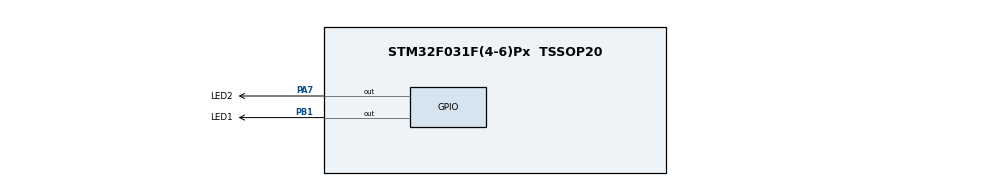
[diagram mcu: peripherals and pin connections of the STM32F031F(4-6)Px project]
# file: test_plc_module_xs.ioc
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Mcu.Family=STM32F0
Mcu.Name=STM32F031F(4-6)Px
Mcu.Package=TSSOP20
NVIC.FLASH_IRQn=true\:0\:0\:false\:false\:true\:true\:true
PA13.Mode=Serial_Wire
PA13.Signal=SYS_SWDIO
PA14.Mode=Serial_Wire
PA14.Signal=SYS_SWCLK
PA7.GPIO_Label=LED2
PA7.Signal=GPIO_Output
PB1.GPIO_Label=LED1
PB1.PinState=GPIO_PIN_SET
PB1.Signal=GPIO_Output
ProjectManager.HeapSize=0x600
ProjectManager.StackSize=0x600
ProjectManager.TargetToolchain=MDK-ARM V5
RCC.AHBFreq_Value=8000000
RCC.APB1Freq_Value=8000000
RCC.APB1TimFreq_Value=8000000
RCC.HCLKFreq_Value=8000000
RCC.HSE_VALUE=16000000
RCC.PLLMUL=RCC_PLL_MUL3
RCC.SYSCLKFreq_VALUE=8000000
board=custom

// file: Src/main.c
/* USER CODE BEGIN Header */
/**
  ******************************************************************************
  * @file           : main.c
  * @brief          : Main program body
  ******************************************************************************
  * @attention
  *
  * <h2><center>&copy; Copyright (c) 2019 STMicroelectronics.
  * All rights reserved.</center></h2>
  *
  * This software component is licensed by ST under BSD 3-Clause license,
  * the "License"; You may not use this file except in compliance with the
  * License. You may obtain a copy of the License at:
  *                        opensource.org/licenses/BSD-3-Clause
  *
  ******************************************************************************
  */
/* USER CODE END Header */

#include "main.h"
#include "gpio.h"

/* USER CODE BEGIN PV */
#define BOOT_FLAG_ADDRESS   0x08000000U
#define FW_START_ADDR       0x08004000U
/* USER CODE END PV */

void SystemClock_Config(void);
/* USER CODE BEGIN PFP */
/**Force VectorTable to specific memory position defined in linker*/
volatile uint32_t VectorTable[48] __attribute__((section(".RAMVectorTable")));

void remapMemToSRAM( void )
{
    uint32_t vecIndex = 0;
    __disable_irq();

    for(vecIndex = 0; vecIndex < 48; vecIndex++){
        VectorTable[vecIndex] = *(volatile uint32_t*)(FW_START_ADDR + (vecIndex << 2));
    }

    __HAL_SYSCFG_REMAPMEMORY_SRAM();

    __enable_irq();
}

/* USER CODE END PFP */

int main(void)
{
  /* USER CODE BEGIN 1 */
  remapMemToSRAM();
  /* USER CODE END 1 */

  /* MCU Configuration--------------------------------------------------------*/

  /* Reset of all peripherals, Initializes the Flash interface and the Systick. */
  HAL_Init();

  /* Configure the system clock */
  SystemClock_Config();

  /* Initialize all configured peripherals */
  MX_GPIO_Init();

  /* Infinite loop */
  while (1)
  {

    /* USER CODE BEGIN 3 */
    HAL_GPIO_TogglePin(LED2_GPIO_Port, LED2_Pin);
    HAL_Delay(100);
  }
  /* USER CODE END 3 */
}

void SystemClock_Config(void)
{
  LL_FLASH_SetLatency(LL_FLASH_LATENCY_0);

  if(LL_FLASH_GetLatency() != LL_FLASH_LATENCY_0)
  {
  Error_Handler();
  }
  LL_RCC_HSI_Enable();

   /* Wait till HSI is ready */
  while(LL_RCC_HSI_IsReady() != 1)
  {

  }
  LL_RCC_HSI_SetCalibTrimming(16);
  LL_RCC_SetAHBPrescaler(LL_RCC_SYSCLK_DIV_1);
  LL_RCC_SetAPB1Prescaler(LL_RCC_APB1_DIV_1);
  LL_RCC_SetSysClkSource(LL_RCC_SYS_CLKSOURCE_HSI);

   /* Wait till System clock is ready */
  while(LL_RCC_GetSysClkSource() != LL_RCC_SYS_CLKSOURCE_STATUS_HSI)
  {

  }
  LL_SetSystemCoreClock(8000000);
}

void Error_Handler(void)
{
}

/************************ (C) COPYRIGHT STMicroelectronics *****END OF FILE****/
